# S32R372 register map
Vendor: Freescale Semiconductor, Inc.; Series: Qorivva; File version: 1.6
Registers are 32-bit, read-write, reset 0x0 unless marked. A register's access mark holds for its fields unless they carry their own. Offsets are from the block's base; [hi:lo] are bit positions; {n}, {i} and the like mark numbered series; 'fields as' and 'values as' point back to an identical list.

## CAN_2 — Flex Controller Area Network module
Base 0xFBEC0000; register names take the prefix CAN_2_
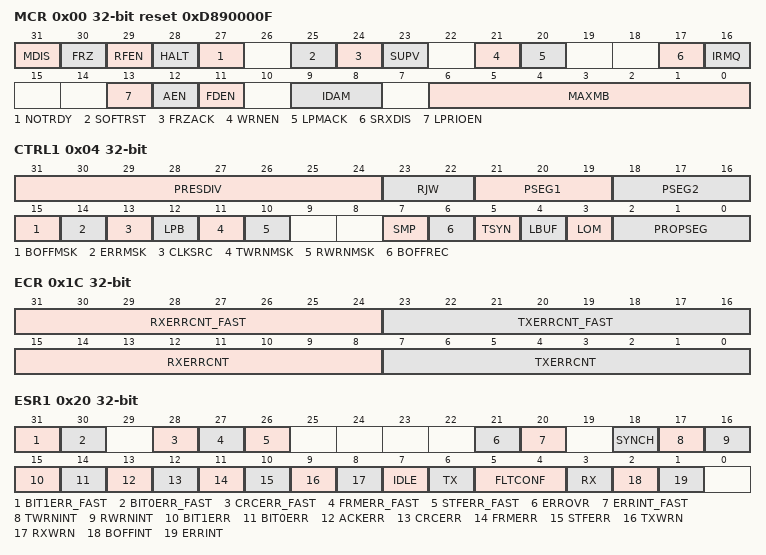
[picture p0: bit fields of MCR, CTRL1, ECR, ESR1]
0x00 MCR reset 0xD890000F — Module Configuration Register
  [31] MDIS — Module Disable
    0=Enable the FlexCAN module; 1=Disable the FlexCAN module
  [30] FRZ — Freeze Enable
    0=Not enabled to enter Freeze mode; 1=Enabled to enter Freeze mode
  [29] RFEN — Rx FIFO Enable
    0=Rx FIFO not enabled; 1=Rx FIFO enabled
  [28] HALT — Halt FlexCAN
    0=No Freeze mode request; 1=Enters Freeze mode if the FRZ bit is asserted
  [27] NOTRDY ro — FlexCAN Not Ready
    0=FlexCAN module is either in Normal mode, Listen-Only mode or Loop-Back mode; 1=FlexCAN module is either in Disable mode, Stop mode or Freeze mode
  [25] SOFTRST — Soft Reset
    0=No reset request; 1=Resets the registers affected by soft reset
  [24] FRZACK ro — Freeze Mode Acknowledge
    0=FlexCAN not in Freeze mode, prescaler running; 1=FlexCAN in Freeze mode, prescaler stopped
  [23] SUPV — Supervisor Mode
    0=FlexCAN is in User mode. Affected registers allow both Supervisor and Unrestricted accesses.; 1=FlexCAN is in Supervisor mode. Affected registers allow only Supervisor access. Unrestricted access behaves as though the access was done to an unimplemented register location.
  [21] WRNEN — Warning Interrupt Enable
    0=TWRNINT and RWRNINT bits are zero, independent of the values in the error counters; 1=TWRNINT and RWRNINT bits are set when the respective error counter transitions from less than 96 to greater than or equal to 96
  [20] LPMACK ro — Low-Power Mode Acknowledge
    0=FlexCAN is not in a low-power mode; 1=FlexCAN is in a low-power mode
  [17] SRXDIS — Self Reception Disable
    0=Self reception enabled; 1=Self reception disabled
  [16] IRMQ — Individual Rx Masking And Queue Enable
    0=Individual Rx masking and queue feature are disabled. For backward compatibility with legacy applications, the reading of C/S word locks the MB even if it is EMPTY.; 1=Individual Rx masking and queue feature are enabled
  [13] LPRIOEN — Local Priority Enable
    0=Local Priority disabled; 1=Local Priority enabled
  [12] AEN — Abort Enable
    0=Abort disabled; 1=Abort enabled
  [11] FDEN — CAN FD operation enable
    1=CAN FD is enabled. FlexCAN is able to receive and transmit messages in both CAN FD and CAN 2.0 formats.; 0=CAN FD is disabled. FlexCAN is able to receive and transmit messages in CAN 2.0 format.
  [9:8] IDAM — ID Acceptance Mode
    0=Format A: One full ID (standard and extended) per ID Filter Table element; 1=Format B: Two full standard IDs or two partial 14-bit (standard and extended) IDs per ID Filter Table element; 2=Format C: Four partial 8-bit Standard IDs per ID Filter Table element; 3=Format D: All frames rejected
  [6:0] MAXMB — Number Of The Last Message Buffer
0x04 CTRL1 — Control 1 register
  [31:24] PRESDIV — Prescaler Division Factor
  [23:22] RJW — Resync Jump Width
  [21:19] PSEG1 — Phase Segment 1
  [18:16] PSEG2 — Phase Segment 2
  [15] BOFFMSK — Bus Off Interrupt Mask
    0=Bus Off interrupt disabled; 1=Bus Off interrupt enabled
  [14] ERRMSK — Error Interrupt Mask
    0=Error interrupt disabled; 1=Error interrupt enabled
  [13] CLKSRC — CAN Engine Clock Source
    0=The CAN engine clock source is the oscillator clock. Under this condition, the oscillator clock frequency must be lower than the bus clock.; 1=The CAN engine clock source is the peripheral clock
  [12] LPB — Loop Back Mode
    0=Loop Back disabled; 1=Loop Back enabled
  [11] TWRNMSK — Tx Warning Interrupt Mask
    0=Tx Warning Interrupt disabled; 1=Tx Warning Interrupt enabled
  [10] RWRNMSK — Rx Warning Interrupt Mask
    0=Rx Warning Interrupt disabled; 1=Rx Warning Interrupt enabled
  [7] SMP — CAN Bit Sampling
    0=Just one sample is used to determine the bit value; 1=Three samples are used to determine the value of the received bit: the regular one (sample point) and 2 preceding samples; a majority rule is used
  [6] BOFFREC — Bus Off Recovery
    0=Automatic recovering from Bus Off state enabled; 1=Automatic recovering from Bus Off state disabled
  [5] TSYN — Timer Sync
    0=Timer Sync feature disabled; 1=Timer Sync feature enabled
  [4] LBUF — Lowest Buffer Transmitted First
    0=Buffer with highest priority is transmitted first; 1=Lowest number buffer is transmitted first
  [3] LOM — Listen-Only Mode
    0=Listen-Only mode is deactivated; 1=FlexCAN module operates in Listen-Only mode
  [2:0] PROPSEG — Propagation Segment
0x08 TIMER — Free Running Timer
  [15:0] TIMER — Timer Value
0x10 RXMGMASK reset not defined — Rx Mailboxes Global Mask Register
  [31:0] MG — Rx Mailboxes Global Mask Bits
    0=The corresponding bit in the filter is "don't care."; 1=The corresponding bit in the filter is checked
0x14 RX14MASK reset not defined
  [31:0] RX14M — Rx Buffer 14 Mask Bits
    values as RXMGMASK.MG
0x18 RX15MASK reset not defined
  [31:0] RX15M — Rx Buffer 15 Mask Bits
    values as RXMGMASK.MG
0x1C ECR — Error Counter
  [31:24] RXERRCNT_FAST — Receive Error Counter for fast bits
  [23:16] TXERRCNT_FAST — Transmit Error Counter for fast bits
  [15:8] RXERRCNT — Receive Error Counter
  [7:0] TXERRCNT — Transmit Error Counter
0x20 ESR1 — Error and Status 1 register
  [31] BIT1ERR_FAST ro — Bit1 Error in the Data Phase of CAN FD frames with the BRS bit set
    0=No such occurrence; 1=At least one bit sent as recessive is received as dominant
  [30] BIT0ERR_FAST ro — Bit0 Error in the Data Phase of CAN FD frames with the BRS bit set
    0=No such occurrence; 1=At least one bit sent as dominant is received as recessive
  [28] CRCERR_FAST ro — Cyclic Redundancy Check Error in the CRC field of CAN FD frames with the BRS bit set
    0=No such occurrence; 1=A CRC error occurred since last read of this register
  [27] FRMERR_FAST ro — Form Error in the Data Phase of CAN FD frames with the BRS bit set
    0=No such occurrence; 1=A Form Error occurred since last read of this register
  [26] STFERR_FAST ro — Stuffing Error in the Data Phase of CAN FD frames with the BRS bit set
    0=No such occurrence; 1=A Stuffing Error occurred since last read of this register
  [21] ERROVR — Error Overrun bit
    0=Overrun has not occurred; 1=Overrun has occurred
  [20] ERRINT_FAST — Error Interrupt for errors detected in the Data Phase of CAN FD frames with the BRS bit set
    0=No such occurrence; 1=Indicates setting of any Error Bit detected in the Data Phase of CAN FD frames with the BRS bit set
  [18] SYNCH ro — CAN Synchronization Status
    0=FlexCAN is not synchronized to the CAN bus; 1=FlexCAN is synchronized to the CAN bus
  [17] TWRNINT — Tx Warning Interrupt Flag
    0=No such occurrence; 1=The Tx error counter transitioned from less than 96 to greater than or equal to 96
  [16] RWRNINT — Rx Warning Interrupt Flag
    0=No such occurrence; 1=The Rx error counter transitioned from less than 96 to greater than or equal to 96
  [15] BIT1ERR ro — Bit1 Error
    values as BIT1ERR_FAST
  [14] BIT0ERR ro — Bit0 Error
    values as BIT0ERR_FAST
  [13] ACKERR ro — Acknowledge Error
    0=No such occurrence; 1=An ACK error occurred since last read of this register
  [12] CRCERR ro — Cyclic Redundancy Check Error
    values as CRCERR_FAST
  [11] FRMERR ro — Form Error
    values as FRMERR_FAST
  [10] STFERR ro — Stuffing Error
    values as STFERR_FAST
  [9] TXWRN ro — TX Error Warning
    0=No such occurrence; 1=TXERRCNT is greater than or equal to 96
  [8] RXWRN ro — Rx Error Warning
    0=No such occurrence; 1=RXERRCNT is greater than or equal to 96
  [7] IDLE ro — This bit indicates when CAN bus is in IDLE state
    0=No such occurrence; 1=CAN bus is now IDLE
  [6] TX ro — FlexCAN In Transmission
    0=FlexCAN is not transmitting a message; 1=FlexCAN is transmitting a message
  [5:4] FLTCONF ro — Fault Confinement State
    0=Error Active; 1=Error Passive; 0b1x=Bus Off
  [3] RX ro — FlexCAN In Reception
    0=FlexCAN is not receiving a message; 1=FlexCAN is receiving a message
  [2] BOFFINT — Bus Off Interrupt
    0=No such occurrence; 1=FlexCAN module entered Bus Off state
  [1] ERRINT — Error Interrupt
    0=No such occurrence; 1=Indicates setting of any Error Bit in the Error and Status Register
0x24 IMASK2 — Interrupt Masks 2 register
  [31:0] BUF63TO32M — Buffer MB i Mask
    0=The corresponding buffer Interrupt is disabled; 1=The corresponding buffer Interrupt is enabled
0x28 IMASK1 — Interrupt Masks 1 register
  [31:0] BUF31TO0M — Buffer MB i Mask
    values as IMASK2.BUF63TO32M
0x2C IFLAG2 — Interrupt Flags 2 register
  [31:0] BUF63TO32I — Buffer MB i Interrupt
    0=The corresponding buffer has no occurrence of successfully completed transmission or reception; 1=The corresponding buffer has successfully completed transmission or reception
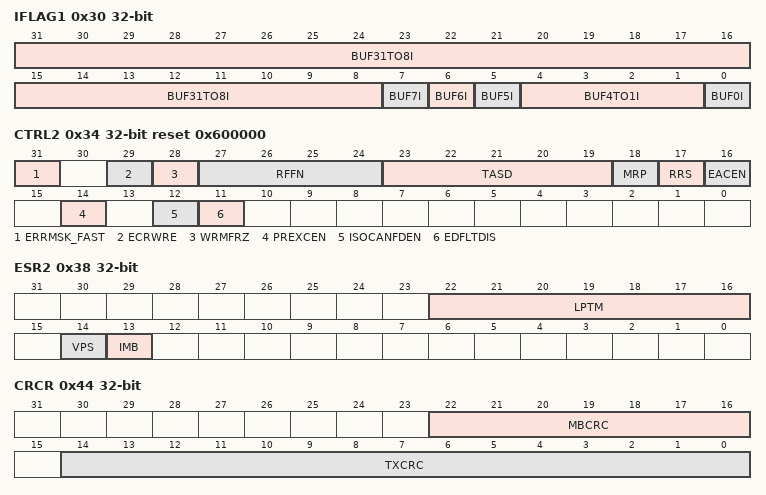
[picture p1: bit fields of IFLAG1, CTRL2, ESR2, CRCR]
0x30 IFLAG1 — Interrupt Flags 1 register
  [31:8] BUF31TO8I — Buffer MBi Interrupt
    values as IFLAG2.BUF63TO32I
  [7] BUF7I — Buffer MB7 Interrupt Or "Rx FIFO Overflow"
    0=No occurrence of MB7 completing transmission/reception when MCR[RFEN]=0, or of Rx FIFO overflow when MCR[RFEN]=1; 1=MB7 completed transmission/reception when MCR[RFEN]=0, or Rx FIFO overflow when MCR[RFEN]=1
  [6] BUF6I — Buffer MB6 Interrupt Or "Rx FIFO Warning"
    0=No occurrence of MB6 completing transmission/reception when MCR[RFEN]=0, or of Rx FIFO almost full when MCR[RFEN]=1; 1=MB6 completed transmission/reception when MCR[RFEN]=0, or Rx FIFO almost full when MCR[RFEN]=1
  [5] BUF5I — Buffer MB5 Interrupt Or "Frames available in Rx FIFO"
    0=No occurrence of MB5 completing transmission/reception when MCR[RFEN]=0, or of frame(s) available in the FIFO, when MCR[RFEN]=1; 1=MB5 completed transmission/reception when MCR[RFEN]=0, or frame(s) available in the Rx FIFO when MCR[RFEN]=1
  [4:1] BUF4TO1I — Buffer MB i Interrupt Or "reserved"
    0=The corresponding buffer has no occurrence of successfully completed transmission or reception when MCR[RFEN]=0; 1=The corresponding buffer has successfully completed transmission or reception when MCR[RFEN]=0
  [0] BUF0I — Buffer MB0 Interrupt Or "reserved"
    values as BUF4TO1I
0x34 CTRL2 reset 0x600000 — Control 2 register
  [31] ERRMSK_FAST — Error Interrupt Mask for errors detected in the Data Phase of fast CAN FD frames
    0=ERRINT_FAST Error interrupt disabled; 1=ERRINT_FAST Error interrupt enabled
  [29] ECRWRE — Error-correction Configuration Register Write Enable
    0=Disable update; 1=Enable update
  [28] WRMFRZ — Write-Access To Memory In Freeze Mode
    0=Maintain the write access restrictions; 1=Enable unrestricted write access to FlexCAN memory
  [27:24] RFFN — Number Of Rx FIFO Filters
  [23:19] TASD — Tx Arbitration Start Delay
  [18] MRP — Mailboxes Reception Priority
    0=Matching starts from Rx FIFO and continues on Mailboxes; 1=Matching starts from Mailboxes and continues on Rx FIFO
  [17] RRS — Remote Request Storing
    0=Remote Response Frame is generated; 1=Remote Request Frame is stored
  [16] EACEN — Entire Frame Arbitration Field Comparison Enable For Rx Mailboxes
    0=Rx Mailbox filter's IDE bit is always compared and RTR is never compared despite mask bits; 1=Enables the comparison of both Rx Mailbox filter's IDE and RTR bit with their corresponding bits within the incoming frame. Mask bits do apply.
  [14] PREXCEN — Protocol Exception Enable
    0=Protocol Exception is disabled; 1=Protocol Exception is enabled
  [12] ISOCANFDEN — ISO CAN FD Enable
    0=FlexCAN operates using the non-ISO CAN FD protocol; 1=FlexCAN operates using the ISO CAN FD protocol (ISO 11898-1)
  [11] EDFLTDIS — Edge Filter Disable
    0=Edge Filter is enabled; 1=Edge Filter is disabled
0x38 ESR2 ro — Error and Status 2 register
  [22:16] LPTM — Lowest Priority Tx Mailbox
  [14] VPS — Valid Priority Status
    0=Contents of IMB and LPTM are invalid; 1=Contents of IMB and LPTM are valid
  [13] IMB — Inactive Mailbox
    0=If ESR2[VPS] is asserted, the ESR2[LPTM] is not an inactive Mailbox; 1=If ESR2[VPS] is asserted, there is at least one inactive Mailbox. LPTM content is the number of the first one.
0x44 CRCR ro — CRC Register
  [22:16] MBCRC — CRC Mailbox
  [14:0] TXCRC — Transmitted CRC value
0x48 RXFGMASK reset not defined — Rx FIFO Global Mask register
  [31:0] FGM — Rx FIFO Global Mask Bits
    values as RXMGMASK.MG
0x4C RXFIR ro reset not defined — Rx FIFO Information Register
  [8:0] IDHIT — Identifier Acceptance Filter Hit Indicator
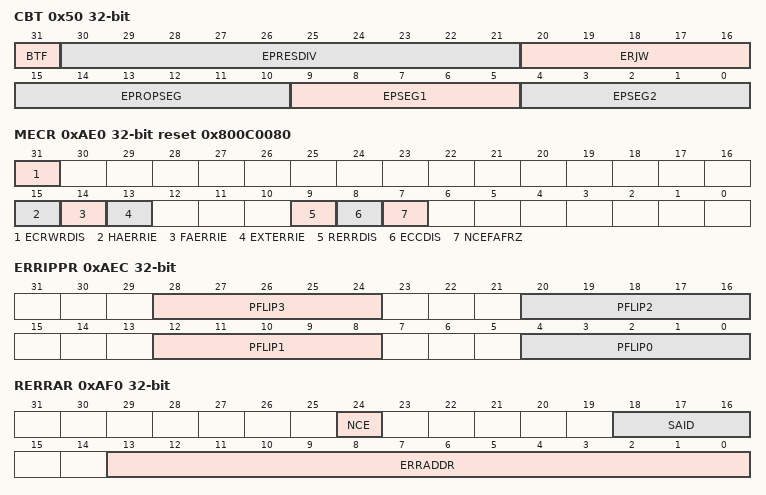
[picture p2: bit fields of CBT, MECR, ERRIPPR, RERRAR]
0x50 CBT — CAN Bit Timing Register
  [31] BTF — Bit Timing Format Enable
    0=Extended bit time definitions disabled; 1=Extended bit time definitions enabled
  [30:21] EPRESDIV — Extended Prescaler Division Factor
  [20:16] ERJW — Extended Resync Jump Width
  [15:10] EPROPSEG — Extended Propagation Segment
  [9:5] EPSEG1 — Extended Phase Segment 1
  [4:0] EPSEG2 — Extended Phase Segment 2
0x6C IMASK3 — Interrupt Masks 3 Register
  [31:0] BUF95TO64M — Buffer MB i Mask
    values as IMASK2.BUF63TO32M
0x74 IFLAG3 — Interrupt Flags 3 Register
  [31:0] BUF95TO64 — Buffer MB i Interrupt
    values as IFLAG2.BUF63TO32I
{0x880+4i} RXIMR{i} (i=0..95) reset not defined — Rx Individual Mask Registers
  [31:0] MI — Individual Mask Bits
    values as RXMGMASK.MG
0xAE0 MECR reset 0x800C0080 — Memory Error Control Register
  [31] ECRWRDIS — Error Configuration Register Write Disable
    0=Write is enabled; 1=Write is disabled
  [15] HAERRIE — Host Access Error Injection Enable
    0=Injection is disabled; 1=Injection is enabled
  [14] FAERRIE — FlexCAN Access Error Injection Enable
    0=Injection is disabled; 1=Injection is enabled
  [13] EXTERRIE — Extended Error Injection Enable
    0=Error injection is applied only to the 32-bit word; 1=Error injection is applied to the 64-bit word
  [9] RERRDIS — Error Report Disable
    0=Enable updates of the error report registers; 1=Disable updates of the error report registers
  [8] ECCDIS — Error Correction Disable
    0=Enable memory error correction; 1=Disable memory error correction
  [7] NCEFAFRZ — Non-Correctable Errors In FlexCAN Access Put Device In Freeze Mode
    0=Keep normal operation; 1=Put FlexCAN in Freeze mode (according to the "Freeze mode" section)
0xAE4 ERRIAR — Error Injection Address Register
  [13:0] INJADDR — Error Injection Address
0xAE8 ERRIDPR — Error Injection Data Pattern Register
  [31:0] DFLIP — Data flip pattern
0xAEC ERRIPPR — Error Injection Parity Pattern Register
  [28:24] PFLIP3 — Parity Flip Pattern For Byte 3 (most significant)
  [20:16] PFLIP2 — Parity Flip Pattern For Byte 2
  [12:8] PFLIP1 — Parity Flip Pattern For Byte 1
  [4:0] PFLIP0 — Parity Flip Pattern For Byte 0 (Least Significant)
0xAF0 RERRAR ro — Error Report Address Register
  [24] NCE — Non-Correctable Error
    0=Reporting a correctable-error; 1=Reporting a non-correctable error
  [18:16] SAID — SAID[2] - Identification of the requestor of the memory read request: 0 = Requested by FlexCAN internal processes 1 = Requested by Host (CPU) SAID[1] - Details of FlexCAN operation: 0 = Move 1 = Scanning SAID[0] - Operation that requested the memory read: 0 = Transmission 1 = Reception Source of memory access SAID[2:0] Error during
  [13:0] ERRADDR — Address Where The Error Was Detected
0xAF4 RERRDR ro — Error Report Data Register
  [31:0] RDATA — Raw data word read from memory with error
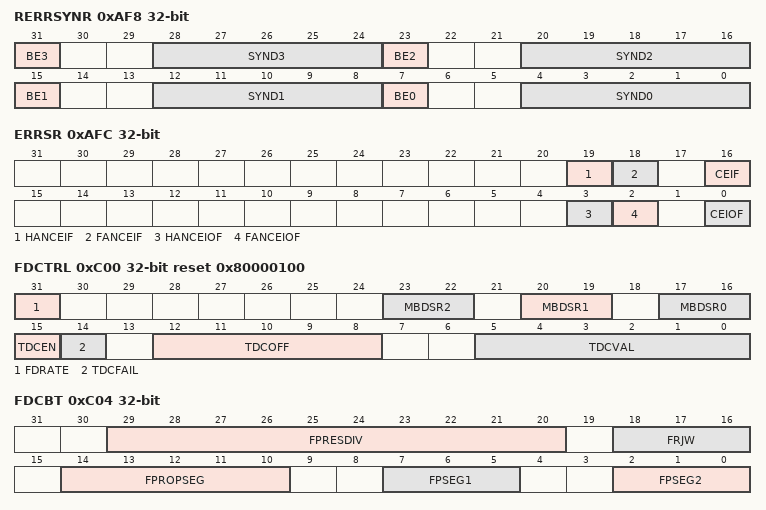
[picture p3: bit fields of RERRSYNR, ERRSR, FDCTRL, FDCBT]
0xAF8 RERRSYNR ro — Error Report Syndrome Register
  [31] BE3 — Byte Enabled For Byte 3 (Most Significant)
    0=The byte was not read; 1=The byte was read
  [28:24] SYND3 — Error Syndrome For Byte 3 (Most Significant)
  [23] BE2 — Byte Enabled For Byte 2
    0=The byte was not read; 1=The byte was read
  [20:16] SYND2 — Error Syndrome For Byte 2
  [15] BE1 — Byte Enabled For Byte 1
    0=The byte was not read; 1=The byte was read
  [12:8] SYND1 — Error Syndrome for Byte 1
  [7] BE0 — Byte Enabled For Byte 0 (least significant)
    0=The byte was not read; 1=The byte was read
  [4:0] SYND0 — Error Syndrome For Byte 0 (least significant)
0xAFC ERRSR — Error Status Register
  [19] HANCEIF — Host Access With Non-Correctable Error Interrupt Flag
    0=No non-correctable errors were detected in Host accesses so far; 1=A non-correctable error was detected in a Host access
  [18] FANCEIF — FlexCAN Access With Non-Correctable Error Interrupt Flag
    0=No non-correctable errors were detected in FlexCAN accesses so far; 1=A non-correctable error was detected in a FlexCAN access
  [16] CEIF — Correctable Error Interrupt Flag
    0=No correctable errors were detected so far; 1=A correctable error was detected
  [3] HANCEIOF — Host Access With Non-Correctable Error Interrupt Overrun Flag
    0=No overrun on non-correctable errors in Host access; 1=Overrun on non-correctable errors in Host access
  [2] FANCEIOF — FlexCAN Access With Non-Correctable Error Interrupt Overrun Flag
    0=No overrun on non-correctable errors in FlexCAN access; 1=Overrun on non-correctable errors in FlexCAN access
  [0] CEIOF — Correctable Error Interrupt Overrun Flag
    0=No overrun on correctable errors; 1=Overrun on correctable errors
0xC00 FDCTRL reset 0x80000100 — CAN FD Control Register
  [31] FDRATE — Bit Rate Switch Enable
    0=Transmit a frame in nominal rate. The BRS bit in the Tx MB has no effect.; 1=Transmit a frame with bit rate switching if the BRS bit in the Tx MB is recessive
  [23:22] MBDSR2 — Message Buffer Data Size for Region 2
    0=Selects 8 bytes per Message Buffer; 1=Selects 16 bytes per Message Buffer; 2=Selects 32 bytes per Message Buffer; 3=Selects 64 bytes per Message Buffer
  [20:19] MBDSR1 — Message Buffer Data Size for Region 1
    values as MBDSR2
  [17:16] MBDSR0 — Message Buffer Data Size for Region 0
    values as MBDSR2
  [15] TDCEN — Transceiver Delay Compensation Enable
    0=TDC is disabled; 1=TDC is enabled
  [14] TDCFAIL — Transceiver Delay Compensation Fail
    0=Measured loop delay is in range; 1=Measured loop delay is out of range
  [12:8] TDCOFF — Transceiver Delay Compensation Offset
  [5:0] TDCVAL ro — Transceiver Delay Compensation Value
0xC04 FDCBT — CAN FD Bit Timing Register
  [29:20] FPRESDIV — Fast Prescaler Division Factor
  [18:16] FRJW — Fast Resync Jump Width
  [14:10] FPROPSEG — Fast Propagation Segment
  [7:5] FPSEG1 — Fast Phase Segment 1
  [2:0] FPSEG2 — Fast Phase Segment 2
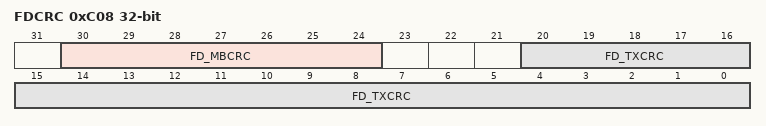
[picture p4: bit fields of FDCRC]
0xC08 FDCRC ro — CAN FD CRC Register
  [30:24] FD_MBCRC — CRC Mailbox Number for FD_TXCRC
  [20:0] FD_TXCRC — Extended Transmitted CRC value

## CAN_0 — Flex Controller Area Network module
Base 0xFFEC0000; register names take the prefix CAN_0_
Registers as CAN_2.
